AUTOSAR XML (schema 321)
standard types defined: Boolean, UInt8
package /ComponentType
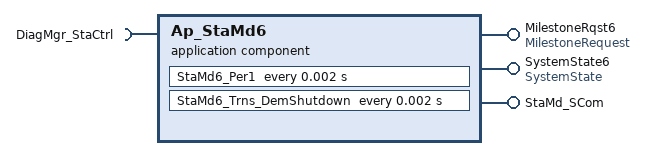
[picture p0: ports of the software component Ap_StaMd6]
  application software component type Ap_StaMd6
    provide port MilestoneRqst6: provided-interface=MilestoneRequest
      provided-com-specs:
        operation=WarmInitMilestoneComplete, queue-length=1
        operation=WarmInitMilestoneNotComplete, queue-length=1
    provide port SystemState6: mode-switch-com-spec{mode-group=Mode, queue-length=1}, provided-interface=SystemState
    provide port StaMd_SCom: provided-com-specs=[{operation=EcuReset, queue-length=1}, {operation=FBLTransitionReq, queue-length=1}], provided-interface=StaMd_SCom
    require port DiagMgr_StaCtrl: client-com-spec=Shutdown, required-interface=DiagMgr_StaCtrl
  internal behavior Ap_StaMd6_InternalBehavior: component=Ap_StaMd6
    operation invoked event OIT_MilestoneRqst6_WarmInitMilestoneComplete_MilestoneRqst6_WarmInitMilestoneComplete: start-on-event=MilestoneRqst6_WarmInitMilestoneComplete, operation=MilestoneRqst6.WarmInitMilestoneComplete
    operation invoked event OIT_MilestoneRqst6_WarmInitMilestoneNotComplete_MilestoneRqst6_WarmInitMilestoneNotComplete: start-on-event=MilestoneRqst6_WarmInitMilestoneNotComplete, operation=MilestoneRqst6.WarmInitMilestoneNotComplete
    timing event TMT_StaMd6_Per1: start-on-event=StaMd6_Per1, period=0.002
    timing event TMT_StaMd6_Trns_DemShutdown: start-on-event=StaMd6_Trns_DemShutdown, period=0.002
    operation invoked event OIT_StaMd_SCom_EcuReset_StaMd_SCom_EcuReset: start-on-event=StaMd_SCom_EcuReset, operation=StaMd_SCom.EcuReset
    operation invoked event OIT_StaMd_SCom_FBLTransitionReq_StaMd_SCom_FBLTransitionReq: start-on-event=StaMd_SCom_FBLTransitionReq, operation=StaMd_SCom.FBLTransitionReq
    exclusive area StaMds6_MilestoneRqst_WARMINIT_ExclArea
    port-api-options:
      enable-take-address=false, indirect-api=false, port=DiagMgr_StaCtrl
      enable-take-address=false, indirect-api=false, port=StaMd_SCom
      enable-take-address=false, indirect-api=false, port=MilestoneRqst6
      enable-take-address=false, indirect-api=false, port=SystemState6
    6 x runnable:
      MilestoneRqst6_WarmInitMilestoneComplete: can-be-invoked-concurrently=true, can-enter-exclusive-area=StaMds6_MilestoneRqst_WARMINIT_ExclArea
      MilestoneRqst6_WarmInitMilestoneNotComplete: can-be-invoked-concurrently=true, can-enter-exclusive-area=StaMds6_MilestoneRqst_WARMINIT_ExclArea
      StaMd6_Trns_DemShutdown
        sync call SC_DiagMgr_StaCtrl_Shutdown: operation=DiagMgr_StaCtrl.Shutdown, timeout=0
      StaMd6_Per1
        mode switch point SWITCH_SystemState6_Mode: mode-group=SystemState6.Mode
      StaMd_SCom_EcuReset
      StaMd_SCom_FBLTransitionReq
  swc implementation Ap_StaMd6_Implementation: behavior=Ap_StaMd6_InternalBehavior
    code-descriptors:
      code Code: type=SRC
package /ComponentType
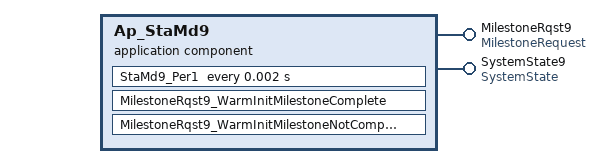
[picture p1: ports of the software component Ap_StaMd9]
  application software component type Ap_StaMd9
    provide port MilestoneRqst9: provided-interface=MilestoneRequest
      provided-com-specs:
        operation=WarmInitMilestoneComplete, queue-length=1
        operation=WarmInitMilestoneNotComplete, queue-length=1
    provide port SystemState9: mode-switch-com-spec{mode-group=Mode, queue-length=1}, provided-interface=SystemState
  internal behavior Ap_StaMd9_InternalBehavior: component=Ap_StaMd9
    operation invoked event OIT_MilestoneRqst9_WarmInitMilestoneComplete_MilestoneRqst9_WarmInitMilestoneComplete: start-on-event=MilestoneRqst9_WarmInitMilestoneComplete, operation=MilestoneRqst9.WarmInitMilestoneComplete
    operation invoked event OIT_MilestoneRqst9_WarmInitMilestoneNotComplete_MilestoneRqst9_WarmInitMilestoneNotComplete: start-on-event=MilestoneRqst9_WarmInitMilestoneNotComplete, operation=MilestoneRqst9.WarmInitMilestoneNotComplete
    timing event TMT_StaMd9_Per1: start-on-event=StaMd9_Per1, period=0.002
    exclusive area StaMds9_MilestoneRqst_WARMINIT_ExclArea
    port-api-options:
      enable-take-address=false, indirect-api=false, port=MilestoneRqst9
      enable-take-address=false, indirect-api=false, port=SystemState9
    runnable MilestoneRqst9_WarmInitMilestoneComplete: can-be-invoked-concurrently=true, can-enter-exclusive-area=StaMds9_MilestoneRqst_WARMINIT_ExclArea
    runnable MilestoneRqst9_WarmInitMilestoneNotComplete: can-be-invoked-concurrently=true, can-enter-exclusive-area=StaMds9_MilestoneRqst_WARMINIT_ExclArea
    runnable StaMd9_Per1
      mode switch point SWITCH_SystemState9_Mode: mode-group=SystemState9.Mode
  swc implementation Ap_StaMd9_Implementation: behavior=Ap_StaMd9_InternalBehavior
    code-descriptors:
      code Code: type=SRC
package /ComponentType
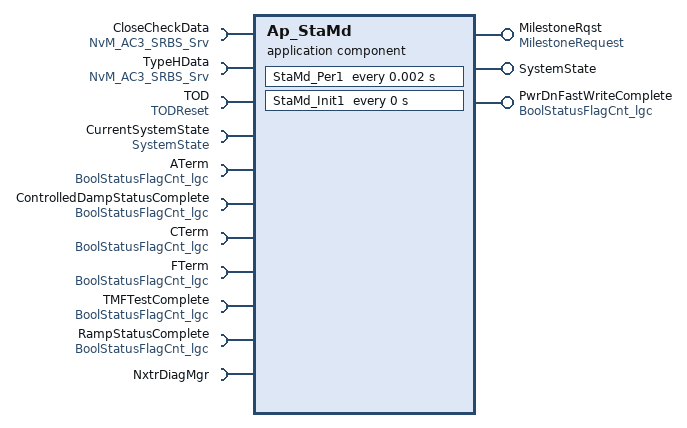
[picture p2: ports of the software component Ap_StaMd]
  application software component type Ap_StaMd
    provide port MilestoneRqst: provided-interface=MilestoneRequest
      provided-com-specs:
        operation=WarmInitMilestoneComplete, queue-length=1
        operation=WarmInitMilestoneNotComplete, queue-length=1
    provide port SystemState: mode-switch-com-spec{mode-group=Mode, queue-length=1}, provided-interface=SystemState
    provide port PwrDnFastWriteComplete: unqueued-sender-com-spec{data-element=Cnt_lgc, can-invalidate=false, init-value=D_FALSE_CNT_LGC}, provided-interface=BoolStatusFlagCnt_lgc
    11 x require port:
      CloseCheckData: required-com-specs=[EraseBlock, GetErrorStatus, InvalidateNvBlock, ReadBlock, SetRamBlockStatus, WriteBlock], required-interface=NvM_AC3_SRBS_Srv
      TypeHData: required-com-specs=[EraseBlock, GetErrorStatus, InvalidateNvBlock, ReadBlock, SetRamBlockStatus, WriteBlock], required-interface=NvM_AC3_SRBS_Srv
      TOD: client-com-spec=OP_SET, required-interface=TODReset
      CurrentSystemState: required-interface=SystemState
      ATerm: unqueued-receiver-com-spec{data-element=Cnt_lgc, handle-invalid=DONT-INVALIDATE, init-value=D_TRUE_CNT_LGC}, required-interface=BoolStatusFlagCnt_lgc
      ControlledDampStatusComplete: unqueued-receiver-com-spec{data-element=Cnt_lgc, handle-invalid=DONT-INVALIDATE, init-value=D_FALSE_CNT_LGC}, required-interface=BoolStatusFlagCnt_lgc
      CTerm: unqueued-receiver-com-spec{data-element=Cnt_lgc, handle-invalid=DONT-INVALIDATE, init-value=D_FALSE_CNT_LGC}, required-interface=BoolStatusFlagCnt_lgc
      FTerm: unqueued-receiver-com-spec{data-element=Cnt_lgc, handle-invalid=DONT-INVALIDATE, init-value=D_FALSE_CNT_LGC}, required-interface=BoolStatusFlagCnt_lgc
      TMFTestComplete: unqueued-receiver-com-spec{data-element=Cnt_lgc, handle-invalid=DONT-INVALIDATE, init-value=D_FALSE_CNT_LGC}, required-interface=BoolStatusFlagCnt_lgc
      RampStatusComplete: unqueued-receiver-com-spec{data-element=Cnt_lgc, handle-invalid=DONT-INVALIDATE, init-value=D_FALSE_CNT_LGC}, required-interface=BoolStatusFlagCnt_lgc
      NxtrDiagMgr: required-com-specs=[GetNTCActive, GetNTCFailed, GetNTCStatus, SetNTCStatus], required-interface=NxtrDiagMgr
  internal behavior Ap_StaMd_InternalBehavior: component=Ap_StaMd
    operation invoked event OIT_MilestoneRqst_WarmInitMilestoneComplete_MilestoneRqst_WarmInitMilestoneComplete: start-on-event=MilestoneRqst_WarmInitMilestoneComplete, operation=MilestoneRqst.WarmInitMilestoneComplete
    operation invoked event OIT_MilestoneRqst_WarmInitMilestoneNotComplete_MilestoneRqst_WarmInitMilestoneNotComplete: start-on-event=MilestoneRqst_WarmInitMilestoneNotComplete, operation=MilestoneRqst.WarmInitMilestoneNotComplete
    timing event TMT_StaMd_Per1: start-on-event=StaMd_Per1, period=0.002
    timing event StaMd_Init1_InitEvent: start-on-event=StaMd_Init1, period=0
    mode switch event MST_StaMd_Trns1_0: start-on-event=StaMd_Trns1, activation=ENTRY, mode=CurrentSystemState.Mode.OFF
    exclusive area StaMds_MilestoneRqst_WARMINIT_ExclArea
    port-api-options:
      enable-take-address=false, indirect-api=false, port=CloseCheckData
      enable-take-address=false, indirect-api=false, port=TypeHData
      enable-take-address=false, indirect-api=false, port=CurrentSystemState
      enable-take-address=false, indirect-api=false, port=PwrDnFastWriteComplete
      enable-take-address=false, indirect-api=false, port=TOD
      enable-take-address=false, indirect-api=false, port=Ap_StaMd/ATerm
      enable-take-address=false, indirect-api=false, port=Ap_StaMd/ControlledDampStatusComplete
      enable-take-address=false, indirect-api=false, port=Ap_StaMd/CTerm
      enable-take-address=false, indirect-api=false, port=Ap_StaMd/FTerm
      enable-take-address=false, indirect-api=false, port=Ap_StaMd/TMFTestComplete
      enable-take-address=false, indirect-api=false, port=Ap_StaMd/NxtrDiagMgr
      enable-take-address=false, indirect-api=false, port=Ap_StaMd/RampStatusComplete
      enable-take-address=false, indirect-api=false, port=MilestoneRqst
      enable-take-address=false, indirect-api=false, port=SystemState
    5 x runnable:
      MilestoneRqst_WarmInitMilestoneComplete: can-be-invoked-concurrently=true, can-enter-exclusive-area=StaMds_MilestoneRqst_WARMINIT_ExclArea
      MilestoneRqst_WarmInitMilestoneNotComplete: can-be-invoked-concurrently=true, can-enter-exclusive-area=StaMds_MilestoneRqst_WARMINIT_ExclArea
      StaMd_Per1
        6 x data read access:
          READ_ATerm_Cnt_lgc: data-element=ATerm.Cnt_lgc
          READ_ControlledDampStatusComplete_Cnt_lgc: data-element=ControlledDampStatusComplete.Cnt_lgc
          READ_CTerm_Cnt_lgc: data-element=CTerm.Cnt_lgc
          READ_FTerm_Cnt_lgc: data-element=FTerm.Cnt_lgc
          READ_TMFTestComplete_Cnt_lgc: data-element=TMFTestComplete.Cnt_lgc
          READ_RampStatusComplete_Cnt_lgc: data-element=RampStatusComplete.Cnt_lgc
        data write access WRITE_PwrDnFastWriteComplete_Cnt_lgc: data-element=PwrDnFastWriteComplete.Cnt_lgc
        mode switch point SWITCH_SystemState_Mode: mode-group=SystemState.Mode
        sync call SC_CloseCheckData_GetErrorStatus: operation=CloseCheckData.GetErrorStatus, timeout=0
        sync call SC_CloseCheckData_WriteBlock: operation=CloseCheckData.WriteBlock, timeout=0
        sync call SC_TOD_OP_SET: operation=TOD.OP_SET, timeout=0
      StaMd_Init1
        sync call SC_CloseCheckData_WriteBlock: operation=CloseCheckData.WriteBlock, timeout=0
        sync call SC_NxtrDiagMgr_SetNTCStatus: operation=NxtrDiagMgr.SetNTCStatus, timeout=0
      StaMd_Trns1
        sync call SC_TypeHData_WriteBlock: operation=TypeHData.WriteBlock, timeout=0
  swc implementation Ap_StaMd_Implementation: behavior=Ap_StaMd_InternalBehavior
    code-descriptors:
      code Code: type=SRC
package /ComponentType
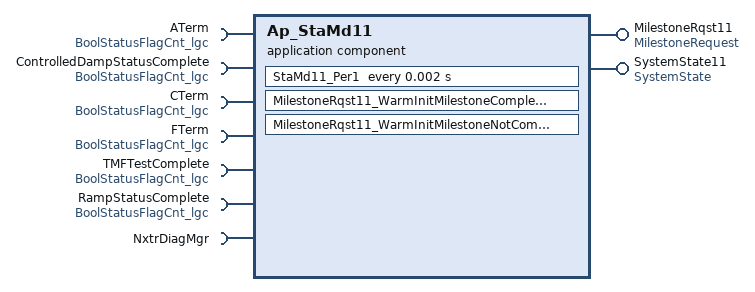
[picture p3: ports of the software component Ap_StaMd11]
  application software component type Ap_StaMd11
    provide port MilestoneRqst11: provided-interface=MilestoneRequest
      provided-com-specs:
        operation=WarmInitMilestoneComplete, queue-length=1
        operation=WarmInitMilestoneNotComplete, queue-length=1
    provide port SystemState11: mode-switch-com-spec{mode-group=Mode, queue-length=1}, provided-interface=SystemState
    7 x require port:
      ATerm: unqueued-receiver-com-spec{data-element=Cnt_lgc, handle-invalid=DONT-INVALIDATE, init-value=D_TRUE_CNT_LGC}, required-interface=BoolStatusFlagCnt_lgc
      ControlledDampStatusComplete: unqueued-receiver-com-spec{data-element=Cnt_lgc, handle-invalid=DONT-INVALIDATE, init-value=D_FALSE_CNT_LGC}, required-interface=BoolStatusFlagCnt_lgc
      CTerm: unqueued-receiver-com-spec{data-element=Cnt_lgc, handle-invalid=DONT-INVALIDATE, init-value=D_FALSE_CNT_LGC}, required-interface=BoolStatusFlagCnt_lgc
      FTerm: unqueued-receiver-com-spec{data-element=Cnt_lgc, handle-invalid=DONT-INVALIDATE, init-value=D_FALSE_CNT_LGC}, required-interface=BoolStatusFlagCnt_lgc
      TMFTestComplete: unqueued-receiver-com-spec{data-element=Cnt_lgc, handle-invalid=DONT-INVALIDATE, init-value=D_FALSE_CNT_LGC}, required-interface=BoolStatusFlagCnt_lgc
      RampStatusComplete: unqueued-receiver-com-spec{data-element=Cnt_lgc, handle-invalid=DONT-INVALIDATE, init-value=D_FALSE_CNT_LGC}, required-interface=BoolStatusFlagCnt_lgc
      NxtrDiagMgr: required-com-specs=[GetNTCActive, GetNTCFailed, GetNTCStatus, SetNTCStatus], required-interface=NxtrDiagMgr
  internal behavior Ap_StaMd11_InternalBehavior: component=Ap_StaMd11
    operation invoked event OIT_MilestoneRqst11_WarmInitMilestoneComplete_MilestoneRqst11_WarmInitMilestoneComplete: start-on-event=MilestoneRqst11_WarmInitMilestoneComplete, operation=MilestoneRqst11.WarmInitMilestoneComplete
    operation invoked event OIT_MilestoneRqst11_WarmInitMilestoneNotComplete_MilestoneRqst11_WarmInitMilestoneNotComplete: start-on-event=MilestoneRqst11_WarmInitMilestoneNotComplete, operation=MilestoneRqst11.WarmInitMilestoneNotComplete
    timing event TMT_StaMd11_Per1: start-on-event=StaMd11_Per1, period=0.002
    exclusive area StaMds11_MilestoneRqst_WARMINIT_ExclArea
    port-api-options:
      enable-take-address=false, indirect-api=false, port=Ap_StaMd11/ATerm
      enable-take-address=false, indirect-api=false, port=Ap_StaMd11/ControlledDampStatusComplete
      enable-take-address=false, indirect-api=false, port=Ap_StaMd11/CTerm
      enable-take-address=false, indirect-api=false, port=Ap_StaMd11/FTerm
      enable-take-address=false, indirect-api=false, port=Ap_StaMd11/TMFTestComplete
      enable-take-address=false, indirect-api=false, port=Ap_StaMd11/NxtrDiagMgr
      enable-take-address=false, indirect-api=false, port=Ap_StaMd11/RampStatusComplete
      enable-take-address=false, indirect-api=false, port=MilestoneRqst11
      enable-take-address=false, indirect-api=false, port=SystemState11
    runnable MilestoneRqst11_WarmInitMilestoneComplete: can-be-invoked-concurrently=true, can-enter-exclusive-area=StaMds11_MilestoneRqst_WARMINIT_ExclArea
    runnable MilestoneRqst11_WarmInitMilestoneNotComplete: can-be-invoked-concurrently=true, can-enter-exclusive-area=StaMds11_MilestoneRqst_WARMINIT_ExclArea
    runnable StaMd11_Per1
      6 x data read access:
        READ_ATerm_Cnt_lgc: data-element=ATerm.Cnt_lgc
        READ_ControlledDampStatusComplete_Cnt_lgc: data-element=ControlledDampStatusComplete.Cnt_lgc
        READ_CTerm_Cnt_lgc: data-element=CTerm.Cnt_lgc
        READ_FTerm_Cnt_lgc: data-element=FTerm.Cnt_lgc
        READ_TMFTestComplete_Cnt_lgc: data-element=TMFTestComplete.Cnt_lgc
        READ_RampStatusComplete_Cnt_lgc: data-element=RampStatusComplete.Cnt_lgc
      mode switch point SWITCH_SystemState11_Mode: mode-group=SystemState11.Mode
      sync call SC_NxtrDiagMgr_SetNTCStatus: operation=NxtrDiagMgr.SetNTCStatus, timeout=0
  swc implementation Ap_StaMd11_Implementation: behavior=Ap_StaMd11_InternalBehavior
    code-descriptors:
      code Code: type=SRC
package /Constant
  constant specification D_FALSE_CNT_LGC
    value:
      boolean literal D_FALSE_CNT_LGC: type=Boolean, value=false
  constant specification D_TRUE_CNT_LGC
    value:
      boolean literal D_TRUE_CNT_LGC: type=Boolean, value=true
package /DataType
  array type NvM_DestPtr  # DataPtr Type to be used by WriteBlock, ReadBlock and RestoreBlockDefaults operations. This type is used for all NVRAM blocks
    element NvM_DestPtr: type=UInt8, max-number-of-elements=65535
  7 x integer type:
    IoHwAb_BoolType: lower-limit=0, upper-limit=1
    NTCNumber: lower-limit=0, upper-limit=511
    NvM_RequestResultType: compu {0=NVM_REQ_OK, 1=NVM_REQ_NOT_OK, 2=NVM_REQ_PENDING, 3=NVM_REQ_INTEGRITY_FAILED, 4=NVM_REQ_BLOCK_SKIPPED, 5=NVM_REQ_NV_INVALIDATED}, lower-limit=0, upper-limit=5
    NxtrDiagMgrStatus: compu {0=NTC_STATUS_PASSED, 1=NTC_STATUS_FAILED, 2=NTC_STATUS_PREPASSED, 3=NTC_STATUS_PREFAILED}, lower-limit=0, upper-limit=255
    StaMd_Users: compu {0=STAMD_STOPCTRL, 1=STAMD_VEHPWRMD, 2=STAMD_DIAGMGR, 3=STAMD_PHSDSCNCT, 4=STAMD_MTRDRVR, 5=STAMD_TMPRLMON}, lower-limit=0, upper-limit=15
    NxtrOpCycle: compu {0=NxtrDefaultOpCycle}, lower-limit=0, upper-limit=0
    NxtrOpCycleState: compu {1=NXTR_CYCLE_STATE_START, 2=NXTR_CYCLE_STATE_END}, lower-limit=1, upper-limit=2
package /ModeDclrGroup
  mode declaration group StaMd_Mode: initial-mode=WARMINIT  # EPS System State mode declaration
    4 x mode:
      DISABLE
      OFF
      OPERATE
      WARMINIT
package /PortInterface
  7 x client server interface:
    DiagMgr_StaCtrl
      operation Shutdown
    MilestoneRequest
      operation WarmInitMilestoneComplete
        arg user: type=StaMd_Users, direction=IN
      operation WarmInitMilestoneNotComplete
        arg user: type=StaMd_Users, direction=IN
    NvM_AC3_SRBS_Srv: is-service=true  # Port Interface for NVRAM Blocks of Management Types "NATIVE" or "REDUNDANT" without default values.
      6 x operation:
        EraseBlock: possible-error=NvM_AC3_SRBS_Srv/E_NOT_OK
        GetErrorStatus
          arg ErrorStatus: type=NvM_RequestResultType, direction=OUT
        InvalidateNvBlock: possible-error=NvM_AC3_SRBS_Srv/E_NOT_OK
        ReadBlock: possible-error=NvM_AC3_SRBS_Srv/E_NOT_OK
          arg DstPtr: type=NvM_DestPtr, direction=OUT
        SetRamBlockStatus
          arg RamBlockStatus: type=Boolean, direction=IN
        WriteBlock: possible-error=NvM_AC3_SRBS_Srv/E_NOT_OK
          arg DstPtr: type=NvM_DestPtr, direction=IN
      error E_NOT_OK: error-code=1
    NxtrDiagMgr
      4 x operation, all with possible-error=NxtrDiagMgr/E_NOT_OK:
        GetNTCActive
          arg NTC_Cnt_T_enum: type=NTCNumber, direction=IN
          arg NTCActive_Ptr_T_lgc: type=Boolean, direction=OUT
        GetNTCFailed
          arg NTC_Cnt_T_enum: type=NTCNumber, direction=IN
          arg NTCFailed_Ptr_T_lgc: type=Boolean, direction=OUT
        GetNTCStatus
          arg NTC_Cnt_T_enum: type=NTCNumber, direction=IN
          arg Status_Ptr_T_u08: type=UInt8, direction=OUT
        SetNTCStatus
          arg NTC_Cnt_T_enum: type=NTCNumber, direction=IN
          arg Param_Cnt_T_u08: type=UInt8, direction=IN
          arg Status_Cnt_T_enum: type=NxtrDiagMgrStatus, direction=IN
      error E_NOT_OK: error-code=1
    StaMd_SCom
      operation EcuReset
      operation FBLTransitionReq
    TODReset
      operation OP_SET: possible-error=TODReset/E_NOT_OK
        arg signal: type=IoHwAb_BoolType, direction=IN
      error E_NOT_OK: error-code=1
    WdgM_CheckpointReached: is-service=true
      operation CheckpointReached: possible-error=WdgM_CheckpointReached/E_NOT_OK  # Indicates to the Watchdog Manager that a Checkpoint within a Supervised Entity has been reached.
      error E_NOT_OK: error-code=1
  sender receiver interface BoolStatusFlagCnt_lgc
    data Cnt_lgc: sw-calibration-access=READ-ONLY, type=Boolean
  sender receiver interface SystemState
    mode declaration group prototype Mode: type=StaMd_Mode
